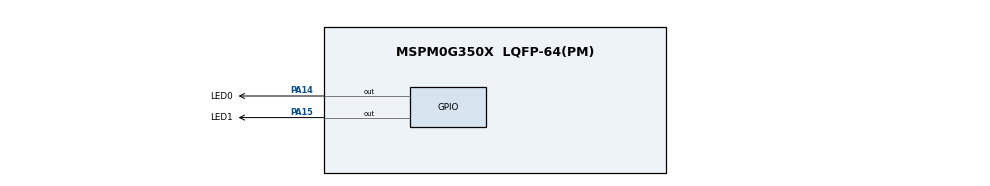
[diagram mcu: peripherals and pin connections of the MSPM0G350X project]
/**
 * @cliArgs --device "MSPM0G350X" --part "Default" --package "LQFP-64(PM)" --product "mspm0_sdk@2.10.00.04"
 * @versions {"tool":"1.26.2+4477"}
 */

/**
 * Import the modules used in this configuration.
 */
const GPIO   = scripting.addModule("/ti/driverlib/GPIO", {}, false);
const GPIO1  = GPIO.addInstance();
const SYSCTL = scripting.addModule("/ti/driverlib/SYSCTL");

/**
 * Write custom configuration values to the imported modules.
 */
const divider9       = system.clockTree["UDIV"];
divider9.divideValue = 2;

const multiplier2         = system.clockTree["PLL_QDIV"];
multiplier2.multiplyValue = 5;

const mux4       = system.clockTree["EXHFMUX"];
mux4.inputSelect = "EXHFMUX_XTAL";

const mux8       = system.clockTree["HSCLKMUX"];
mux8.inputSelect = "HSCLKMUX_SYSPLL0";

const pinFunction4     = system.clockTree["HFXT"];
pinFunction4.inputFreq = 40;

GPIO1.$name                         = "LED";
GPIO1.associatedPins.create(2);
GPIO1.associatedPins[0].$name       = "LED1";
GPIO1.associatedPins[0].pin.$assign = "PA15";
GPIO1.associatedPins[1].$name       = "LED0";
GPIO1.associatedPins[1].pin.$assign = "PA14";

const Board = scripting.addModule("/ti/driverlib/Board", {}, false);

SYSCTL.forceDefaultClkConfig = true;

/**
 * Pinmux solution for unlocked pins/peripherals. This ensures that minor changes to the automatic solver in a future
 * version of the tool will not impact the pinmux you originally saw.  These lines can be completely deleted in order to
 * re-solve from scratch.
 */
Board.peripheral.$suggestSolution          = "DEBUGSS";
Board.peripheral.swclkPin.$suggestSolution = "PA20";
Board.peripheral.swdioPin.$suggestSolution = "PA19";
SYSCTL.peripheral.$suggestSolution         = "SYSCTL";
